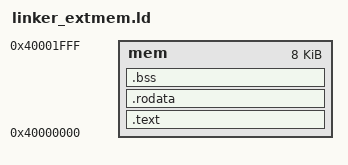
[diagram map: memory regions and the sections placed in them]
OUTPUT_FORMAT("elf32-lm32")
ENTRY(_start)

__DYNAMIC = 0;

MEMORY {
    mem : ORIGIN = 0x40000000, LENGTH = 0x00002000 /* 8k */
}

SECTIONS
{
	.text :
	{
		_ftext = .;
		*(.text .stub .text.* .gnu.linkonce.t.*)
		_etext = .;
	} > mem /* rom */

	.rodata :
	{
		. = ALIGN(4);
		_frodata = .;
		*(.rodata .rodata.* .gnu.linkonce.r.*)
		*(.rodata1)
		_erodata = .;
	} > mem /* rom */

	.bss :
	{
		. = ALIGN(4);
		_fbss = .;
		*(.dynsbss)
		*(.sbss .sbss.* .gnu.linkonce.sb.*)
		*(.scommon)
		*(.dynbss)
		*(.bss .bss.* .gnu.linkonce.b.*)
		*(COMMON)
		. = ALIGN(4);
		_ebss = .;
		_end = .;
	} > mem /* ram */
}

/*PROVIDE(_debug_stack = ORIGIN(ram) + LENGTH(ram) - 4);*/
PROVIDE(_debug_stack = ORIGIN(mem) + LENGTH(mem) - 4);
